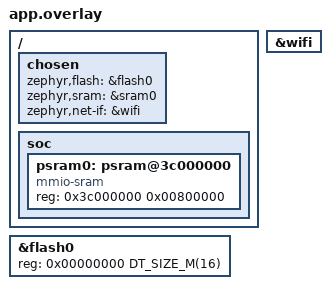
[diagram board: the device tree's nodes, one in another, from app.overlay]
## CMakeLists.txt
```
cmake_minimum_required(VERSION 3.20.0)

# Load WiFi credentials from a separate file if available
if(EXISTS "${CMAKE_CURRENT_SOURCE_DIR}/creds/wifi_credentials.cmake")
    include("${CMAKE_CURRENT_SOURCE_DIR}/creds/wifi_credentials.cmake")
else()
    message(FATAL_ERROR "WiFi credentials not found! Create creds/wifi_credentials.cmake.")
endif()

# Pass WiFi credentials as compiler definitions
add_definitions(-DWIFI_SSID=\"${WIFI_SSID}\" -DWIFI_PSK=\"${WIFI_PSK}\")

# Set board
set(BOARD esp32s3_devkitc/esp32s3/procpu)

# Merge configuration files
set(CONF_FILE ${CMAKE_CURRENT_SOURCE_DIR}/prj.conf)

# Find and include Zephyr
find_package(Zephyr REQUIRED HINTS $ENV{ZEPHYR_BASE})
project(microsite)

# Define source files
target_sources(app PRIVATE src/main.c)

# -------------------- Embed TLS Certificates --------------------

# Set the generated include directory inside the build directory
set(GEN_DIR ${CMAKE_BINARY_DIR}/include/generated/)

# Define certificate and key file paths
set(CERT_FILE ${CMAKE_CURRENT_SOURCE_DIR}/creds/fullchain.pem)
set(KEY_FILE ${CMAKE_CURRENT_SOURCE_DIR}/creds/privkey.pem)

# Ensure the generated directory exists
file(MAKE_DIRECTORY ${GEN_DIR})

# Convert the certificate files into header files
generate_inc_file_for_target(app ${CERT_FILE} ${GEN_DIR}/fullchain.pem.inc)
generate_inc_file_for_target(app ${KEY_FILE} ${GEN_DIR}/privkey.pem.inc)

# Include the generated directory
target_include_directories(app PRIVATE ${GEN_DIR})
```

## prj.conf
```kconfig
# Serial & Console
CONFIG_SERIAL=y
CONFIG_UART_CONSOLE=y
CONFIG_CONSOLE=y
CONFIG_LOG=y

# Main Stack & Memory
CONFIG_MAIN_STACK_SIZE=4096
CONFIG_HEAP_MEM_POOL_SIZE=8192
CONFIG_KERNEL_MEM_POOL=y
CONFIG_SYS_HEAP_RUNTIME_STATS=y
CONFIG_INIT_STACKS=y

# System
CONFIG_SYS_CLOCK_EXISTS=y
CONFIG_GPIO=y

# Flash
CONFIG_FLASH=y
CONFIG_FLASH_MAP=y
CONFIG_FLASH_PAGE_LAYOUT=y

# TLS
# Enable TLS and MbedTLS
CONFIG_TLS_CREDENTIALS=y
CONFIG_MBEDTLS=y
CONFIG_MBEDTLS_BUILTIN=y
CONFIG_MBEDTLS_ENABLE_HEAP=y
CONFIG_MBEDTLS_HEAP_SIZE=65536
CONFIG_MBEDTLS_SSL_MAX_CONTENT_LEN=16384
CONFIG_MBEDTLS_PEM_CERTIFICATE_FORMAT=y
CONFIG_MBEDTLS_SERVER_NAME_INDICATION=y
CONFIG_MBEDTLS_AES_ROM_TABLES=y
CONFIG_MBEDTLS_TLS_VERSION_1_2=y
CONFIG_MBEDTLS_MEMORY_DEBUG=y
CONFIG_MBEDTLS_HAVE_TIME_DATE=y
CONFIG_MBEDTLS_SSL_ALPN=y
CONFIG_MBEDTLS_KEY_EXCHANGE_ECDHE_ECDSA_ENABLED=y
CONFIG_MBEDTLS_KEY_EXCHANGE_ECDH_ECDSA_ENABLED=y
CONFIG_MBEDTLS_ECDH_C=y
CONFIG_MBEDTLS_ECDSA_C=y
CONFIG_MBEDTLS_ECP_C=y
CONFIG_MBEDTLS_ECP_ALL_ENABLED=y
CONFIG_MBEDTLS_CIPHER_AES_ENABLED=y

# Networking Features
CONFIG_NET_TCP=y
CONFIG_NET_TCP_KEEPALIVE=y
CONFIG_NETWORKING=y
CONFIG_POSIX_MAX_FDS=8
CONFIG_WIFI=y
CONFIG_NET_BUF_DATA_SIZE=1500
CONFIG_NET_DHCPV4=y
CONFIG_NET_IF_UNICAST_IPV4_ADDR_COUNT=1
CONFIG_NET_IPV4=y
CONFIG_NET_IPV6=n
CONFIG_NET_L2_WIFI_MGMT=y
CONFIG_NET_MAX_CONTEXTS=5
CONFIG_NET_SOCKETS_POLL_MAX=4
CONFIG_NET_SOCKETS=y
CONFIG_NET_STATISTICS=y
CONFIG_NET_TC_TX_COUNT=1
CONFIG_NET_TCP_MAX_RECV_WINDOW_SIZE=50000
CONFIG_NET_CONFIG_MY_IPV4_ADDR="0.0.0.0"
CONFIG_NET_CONFIG_MY_IPV4_GW="0.0.0.0"
CONFIG_NET_CONFIG_MY_IPV4_NETMASK="255.255.255.0"
CONFIG_NET_CONFIG_SETTINGS=y

# ESP32-S3 Specific Config
CONFIG_ESP_SPIRAM=y
CONFIG_ESP_SPIRAM_HEAP_SIZE=6000000
CONFIG_ESP_SPIRAM_SIZE=7864320
CONFIG_SPIRAM_MODE_OCT=y
CONFIG_SPIRAM_SPEED_80M=y
CONFIG_SPIRAM_ECC_ENABLE=y

# Enable Ethernet (Required for Espressif WiFi Driver)
CONFIG_NET_L2_ETHERNET=y
CONFIG_ETH_INIT_PRIORITY=90
```

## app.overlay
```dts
/ {
    chosen {
        zephyr,flash = &flash0;
        zephyr,sram = &sram0;
        zephyr,net-if = &wifi;
    };

    soc {
        psram0: psram@3c000000 {
            device_type = "memory";
            compatible = "mmio-sram";
            reg = <0x3c000000 0x00800000>;
            status = "okay";
        };
    };
};

&flash0 {
    status = "okay";
    reg = <0x00000000 DT_SIZE_M(16)>;
};

&wifi {
    status = "okay";
};
```

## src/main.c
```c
#include <zephyr/kernel.h>
#include <zephyr/logging/log.h>

LOG_MODULE_REGISTER(JMS_MAIN, LOG_LEVEL_INF);

// ------------------------------------------------------------
// ---------------------- TLS ---------------------------------
// ------------------------------------------------------------
#include <zephyr/net/tls_credentials.h>

// Define embedded certificate and key variables
const uint8_t privkey_data[] = {
#include "privkey.pem.inc"
};

const uint8_t cert_data[] = {
#include "fullchain.pem.inc"
};

#define HTTP_SERVER_CERTIFICATE_TAG 1 // Security tag for Zephyr's TLS system

static void setup_tls(void)
{
    LOG_INF("Registering TLS credentials...");

    // Register server certificate
    if (tls_credential_add(HTTP_SERVER_CERTIFICATE_TAG, TLS_CREDENTIAL_SERVER_CERTIFICATE,
                           cert_data, // Now using the corrected variable
                           sizeof(cert_data)) < 0)
    {
        LOG_ERR("Failed to register public certificate.");
        return;
    }

    // Register private key
    if (tls_credential_add(HTTP_SERVER_CERTIFICATE_TAG, TLS_CREDENTIAL_PRIVATE_KEY,
                           privkey_data, // Now using the corrected variable
                           sizeof(privkey_data)) < 0)
    {
        LOG_ERR("Failed to register private key.");
        return;
    }

    LOG_INF("TLS certificates successfully registered.");
}

static void debug_certificate(void)
{
    LOG_INF("First bytes of certificate: %02X %02X %02X %02X %02X %02X %02X %02X...",
            cert_data[0], cert_data[1], cert_data[2], cert_data[3], cert_data[4],
            cert_data[5], cert_data[6], cert_data[7]);
}

// ------------------------------------------------------------
// ---------------------- WIFI --------------------------------
// ------------------------------------------------------------
// Wifi stuff
#include <zephyr/net/net_if.h>
#include <zephyr/net/wifi_mgmt.h>

#ifndef WIFI_SSID
#define WIFI_SSID "default_ssid"
#endif

#ifndef WIFI_PSK
#define WIFI_PSK "default_psk"
#endif

static struct net_mgmt_event_callback wifi_cb;
static struct net_mgmt_event_callback ipv4_cb;
static K_SEM_DEFINE(wifi_connected, 0, 1);
static K_SEM_DEFINE(ipv4_address_obtained, 0, 1);

static void handle_wifi_connect_result(struct net_mgmt_event_callback* cb)
{
    const struct wifi_status* status = (const struct wifi_status*)cb->info;

    if (status->status)
    {
        LOG_ERR("WiFi connection failed (%d)", status->status);
    }
    else
    {
        LOG_INF("WiFi connected!");
        k_sem_give(&wifi_connected);
    }
}

static void handle_wifi_disconnect_result(struct net_mgmt_event_callback* cb)
{
    LOG_WRN("WiFi disconnected");
    k_sem_take(&wifi_connected, K_NO_WAIT);
}

static void handle_ipv4_result(struct net_if* iface)
{
    char buf[NET_IPV4_ADDR_LEN];

    for (int i = 0; i < NET_IF_MAX_IPV4_ADDR; i++)
    {
        if (iface->config.ip.ipv4->unicast[i].ipv4.addr_type != NET_ADDR_DHCP)
        {
            continue;
        }

        LOG_INF("IPv4 Address: %s",
                net_addr_ntop(AF_INET,
                              &iface->config.ip.ipv4->unicast[i].ipv4.address.in_addr,
                              buf, sizeof(buf)));
        LOG_INF("Subnet: %s",
                net_addr_ntop(AF_INET, &iface->config.ip.ipv4->unicast[i].netmask, buf,
                              sizeof(buf)));
        LOG_INF("Router: %s",
                net_addr_ntop(AF_INET, &iface->config.ip.ipv4->gw, buf, sizeof(buf)));
        LOG_INF("Lease time: %u seconds", iface->config.dhcpv4.lease_time);
    }

    k_sem_give(&ipv4_address_obtained);
}

static void wifi_mgmt_event_handler(struct net_mgmt_event_callback* cb,
                                    uint32_t mgmt_event, struct net_if* iface)
{
    switch (mgmt_event)
    {
    case NET_EVENT_WIFI_CONNECT_RESULT:
        handle_wifi_connect_result(cb);
        break;
    case NET_EVENT_WIFI_DISCONNECT_RESULT:
        handle_wifi_disconnect_result(cb);
        break;
    case NET_EVENT_IPV4_ADDR_ADD:
        handle_ipv4_result(iface);
        break;
    default:
        break;
    }
}

void wifi_connect(void)
{
    struct net_if* iface = net_if_get_default();
    struct wifi_connect_req_params params = {0};

    params.ssid = WIFI_SSID;
    params.psk = WIFI_PSK;
    params.ssid_length = strlen(WIFI_SSID);
    params.psk_length = strlen(WIFI_PSK);
    params.channel = WIFI_CHANNEL_ANY;
    params.security = WIFI_SECURITY_TYPE_PSK;
    params.band = WIFI_FREQ_BAND_2_4_GHZ;
    params.mfp = WIFI_MFP_OPTIONAL;

    LOG_INF("Connecting to SSID: %s", params.ssid);

    if (net_mgmt(NET_REQUEST_WIFI_CONNECT, iface, &params, sizeof(params)))
    {
        LOG_ERR("WiFi Connection Request Failed");
    }
}

// -------------------------------------------------------------
// ---------------------- PSRAM --------------------------------
// -------------------------------------------------------------
// Heap stuff
#include <soc/soc_memory_layout.h>
#include <zephyr/multi_heap/shared_multi_heap.h>

void print_psram_info(void)
{
    uint32_t *p_mem, k;

    LOG_INF("Checking PSRAM...");

    p_mem = shared_multi_heap_aligned_alloc(SMH_REG_ATTR_EXTERNAL, 32,
                                            1024 * sizeof(uint32_t));

    if (p_mem == NULL)
    {
        LOG_ERR("PSRAM memory allocation failed!");
        return;
    }

    for (k = 0; k < 1024; k++)
    {
        p_mem[k] = k;
    }

    for (k = 0; k < 1024; k++)
    {
        if (p_mem[k] != k)
        {
            LOG_ERR("p_mem[%" PRIu32 "]: %" PRIu32 " (expected value %" PRIu32 ")", k,
                    p_mem[k], k);
            break;
        }
    }

    shared_multi_heap_free(p_mem);

    if (k < 1024)
    {
        LOG_ERR("Failed checking memory contents.");
        return;
    }

    LOG_INF("PSRAM check completed.");
}

// -------------------------------------------------------------
// ---------------------- FLASH --------------------------------
// -------------------------------------------------------------
// Flash stuff
#include <zephyr/drivers/flash.h>
#include <zephyr/storage/flash_map.h>

void print_flash_info(void)
{
    const struct device* flash_dev = DEVICE_DT_GET(DT_PARENT(DT_NODELABEL(flash0)));

    if (!device_is_ready(flash_dev))
    {
        LOG_ERR("Flash device not ready!");
        return;
    }

    size_t total_pages = flash_get_page_count(flash_dev);
    struct flash_pages_info page_info;

    // Get size of the first page
    if (flash_get_page_info_by_idx(flash_dev, 0, &page_info) != 0)
    {
        LOG_ERR("Failed to get flash page info");
        return;
    }

    size_t first_page_size = page_info.size;
    bool uniform_size = true;

    // Iterate through all pages to check for size consistency
    for (size_t i = 1; i < total_pages; i++)
    {
        if (flash_get_page_info_by_idx(flash_dev, i, &page_info) != 0)
        {
            LOG_ERR("Error reading page %zu info", i);
            return;
        }

        if (page_info.size != first_page_size)
        {
            uniform_size = false;
            LOG_ERR("Page %zu has different size: %zu bytes", i, page_info.size);
        }
    }

    if (uniform_size)
    {
        size_t total_flash_size = total_pages * first_page_size;
        LOG_INF("All flash pages have the same size: %zu bytes", first_page_size);
        LOG_INF("Total available flash size: %zu bytes (%zu KB, %zu MB)",
                total_flash_size, total_flash_size / 1024,
                total_flash_size / (1024 * 1024));
    }
    else
    {
        LOG_INF("Flash pages have variable sizes");
    }
}

// ------------------------------------------------------------
// ---------------------- MAIN --------------------------------
// ------------------------------------------------------------

int main(void)
{
    // print_psram_info();
    // print_flash_info();

    LOG_INF("Starting WiFi Connection...");

    LOG_INF("WiFi SSID: %s", WIFI_SSID);

    net_mgmt_init_event_callback(&wifi_cb, wifi_mgmt_event_handler,
                                 NET_EVENT_WIFI_CONNECT_RESULT |
                                     NET_EVENT_WIFI_DISCONNECT_RESULT);
    net_mgmt_init_event_callback(&ipv4_cb, wifi_mgmt_event_handler,
                                 NET_EVENT_IPV4_ADDR_ADD);

    net_mgmt_add_event_callback(&wifi_cb);
    net_mgmt_add_event_callback(&ipv4_cb);

    wifi_connect();

    k_sem_take(&wifi_connected, K_FOREVER);
    k_sem_take(&ipv4_address_obtained, K_FOREVER);

    LOG_INF("WiFi Ready!");

    // Initialize TLS before starting the server
    setup_tls();
    debug_certificate();

    return 0;
}
```
